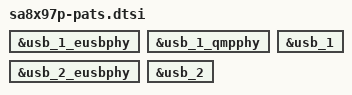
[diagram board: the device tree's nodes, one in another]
// SPDX-License-Identifier: BSD-3-Clause
/*
 * Copyright (c) Qualcomm Technologies, Inc. and/or its subsidiaries.
 */

&usb_1_eusbphy {
	status = "okay";
};

&usb_1_qmpphy {
	status = "okay";
};

&usb_1 {
	status = "okay";
};

&usb_2_eusbphy {
	status = "okay";
};

&usb_2 {
	status = "okay";
};
